# HSUSBOTG register map
Vendor: Texas Instruments
Peripheral module from a debugger description file (folder omap4460).
Registers are 32-bit, access per field, reset 0x0 unless marked. A register's access mark holds for its fields unless they carry their own. Offsets are as the file gives them; lines under a group give offsets from that group; [hi:lo] are bit positions; {n}, {i} and the like mark numbered series; 'fields as' and 'values as' point back to an identical list; <NAME> marks a mode.

## HSUSBOTG
0x400 OTG_REVISION ro reset not defined — OCP standard USB OTG HS core revision number
  [31:0] RESERVED — IP Revision
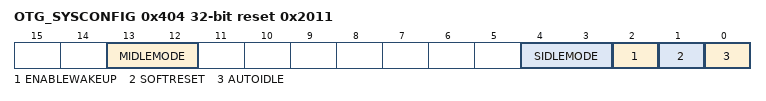
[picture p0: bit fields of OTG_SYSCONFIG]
0x404 OTG_SYSCONFIG reset 0x2011 — OCP standard configuration
  [13:12] MIDLEMODE rw — Master interface power management control. Standby/wait control
    0=Force standby mode. Mstandby asserted unconditionally; 1=No standby mode. Mstandby never asserted.; 2=Smart standby mode. Mstandby asserted when no more activity on the USB master.
  [4:3] SIDLEMODE rw — Slave interface power management control. Req/ack control
    0=Force Idle mode. Sidleack asserted after Midlereq assertion; 1=No idle mode. Sidleack never asserted.; 2=SmartIdle mode. Sidleack asserted after Midlereq assertion when no more activity on the USB. Swakeup is not asserted in this mode.; 3=SmartIdle - Wakeup mode. Sidleack asserted after Midlereq assertion when no more activity on the USB. Swakeup is asserted in this mode if ENABLEWAKEUP is set.
  [2] ENABLEWAKEUP rw — Enable wakeup capability.
    0=Wakeup disabled; 1=Wakeup enabled
  [1] SOFTRESET rw — Software reset bit
    1=Starts softreset sequence
  [0] AUTOIDLE rw — Autoidle bit
    0=Clock always runnning; 1=When no activity on OCP, clock is cut off
0x408 OTG_SYSSTATUS ro reset 0x1 — OCP standard status
  [0] RESETDONE
    0=RESETDONE_0_r (Reset is ongoing); 1=RESETDONE_1_r (Reset is finished.)
0x40C OTG_INTERFSEL reset 0x1 — USB OTG HS interface selection. The interface selection has to be done before the PHY is activated and is not allowed to change when the PHY clock is already running.
  [2:0] PHYSEL rw — PHY interface selection
    0=PHY interface is 8-bit, UTMI+ level 3; 1=PHY interface is 12-pin, 8-bit SDR ULPI; 2=PHY interface is 8-pin, 4-bit DDR ULPI (Non-functional mode in current implementation. Do not use.)
0x410 OTG_SIMENABLE — Enable simulation acceleration features. WARNING: For simulations only, since those features have an impact on USB protocol.
  [0] TM1 rw — Test Mode 1 enabling (timer shortcuts)
0x414 OTG_FORCESTDBY — Enabling MSTANDBY in FORCESTANDBY mode. Programming this register will impact SmartStandby functionality.
  [0] ENABLEFORCE rw — Enabling MSTANDBY to go high
0x418 OTG_BIGENDIAN — Enable BIG ENDIANESS for OCP MASTER
  [0] BIG_ENDIAN rw — Enable BIG ENDIAN in OCP MASTER
